# jbr_MDR1986VE1T register map
Registers are 32-bit, access not given, no defined reset value unless marked. A register's access mark holds for its fields unless they carry their own. Addresses are absolute; registers are grouped by the start of their names; [hi:lo] are bit positions; {n}, {i} and the like mark numbered series; 'fields as' and 'values as' point back to an identical list.

## GPIOF
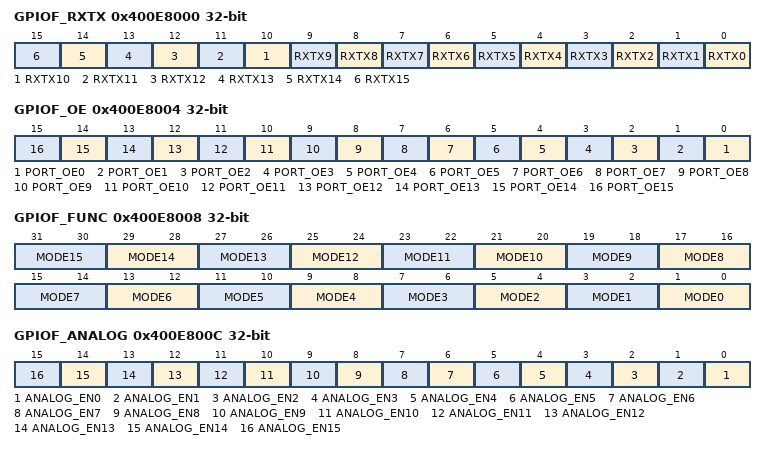
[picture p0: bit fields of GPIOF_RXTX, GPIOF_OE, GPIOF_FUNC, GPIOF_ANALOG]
0x400E8000 GPIOF_RXTX
  [n] RXTX{n} (n=0..15)
0x400E8004 GPIOF_OE
  [n] PORT_OE{n} (n=0..15)
0x400E8008 GPIOF_FUNC
  [2n+1:2n] MODE{n} (n=0..15)
0x400E800C GPIOF_ANALOG
  [n] ANALOG_EN{n} (n=0..15)
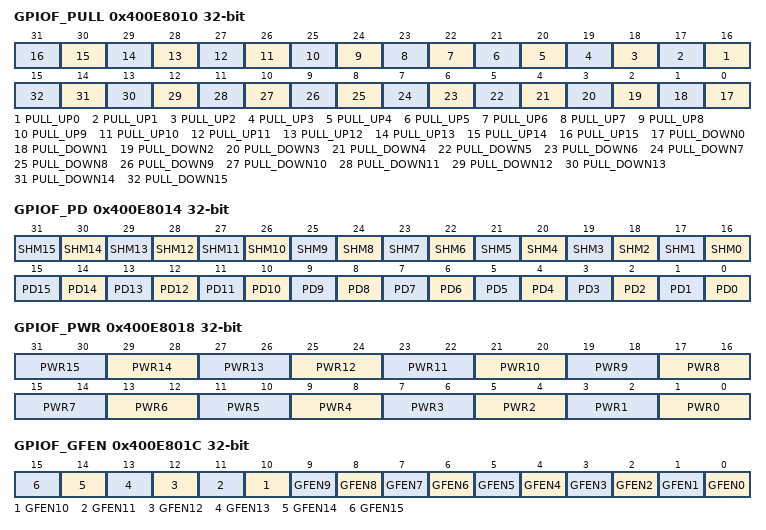
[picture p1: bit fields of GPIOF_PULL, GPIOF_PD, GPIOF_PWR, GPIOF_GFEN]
0x400E8010 GPIOF_PULL
  [n+16] PULL_UP{n} (n=0..15), [n] PULL_DOWN{n} (n=0..15)
0x400E8014 GPIOF_PD
  [n+16] SHM{n} (n=0..15), [n] PD{n} (n=0..15)
0x400E8018 GPIOF_PWR
  [2n+1:2n] PWR{n} (n=0..15)
0x400E801C GPIOF_GFEN
  [n] GFEN{n} (n=0..15)
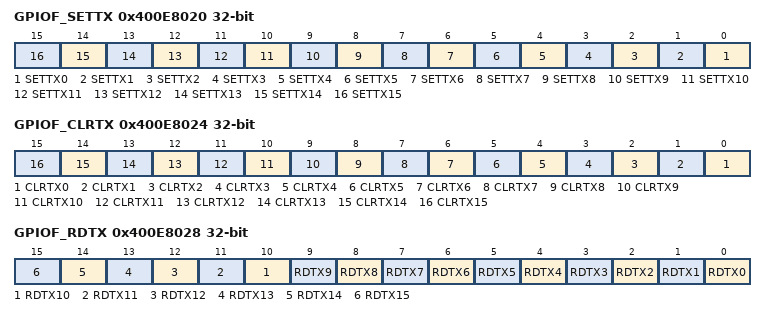
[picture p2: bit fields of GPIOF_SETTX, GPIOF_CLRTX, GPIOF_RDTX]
0x400E8020 GPIOF_SETTX
  [n] SETTX{n} (n=0..15)
0x400E8024 GPIOF_CLRTX
  [n] CLRTX{n} (n=0..15)
0x400E8028 GPIOF_RDTX
  [n] RDTX{n} (n=0..15)

## DMA
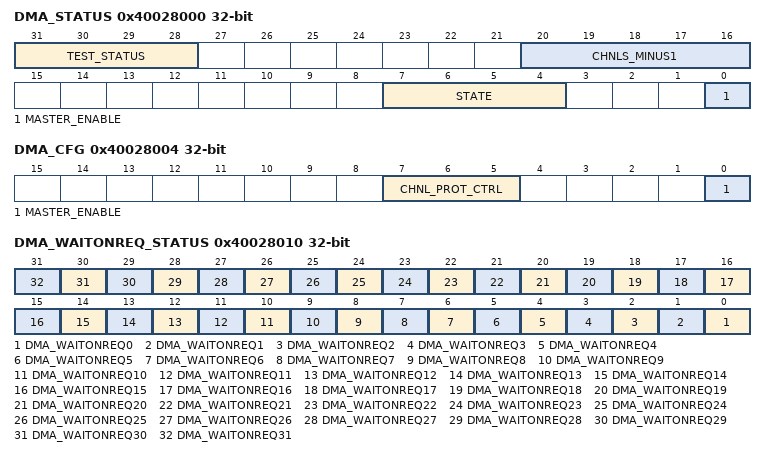
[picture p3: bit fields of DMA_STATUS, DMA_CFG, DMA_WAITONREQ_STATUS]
0x40028000 DMA_STATUS
  [31:28] TEST_STATUS, [20:16] CHNLS_MINUS1, [7:4] STATE, [0] MASTER_ENABLE
0x40028004 DMA_CFG
  [7:5] CHNL_PROT_CTRL, [0] MASTER_ENABLE
0x40028010 DMA_WAITONREQ_STATUS
  [n] DMA_WAITONREQ{n} (n=0..31)

## CHNL
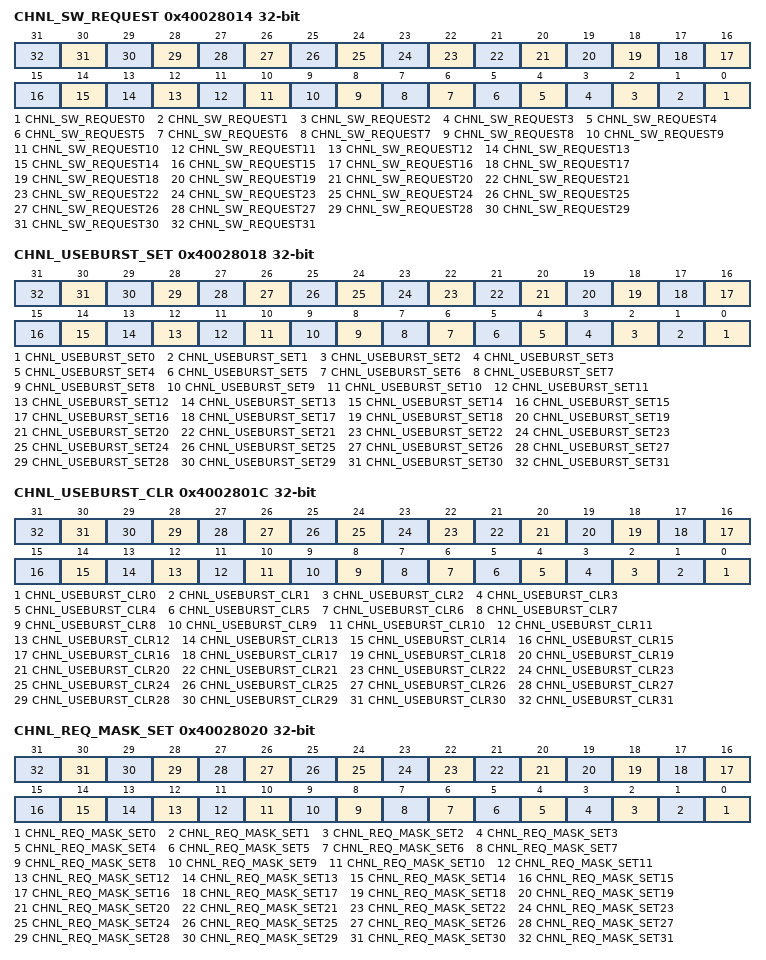
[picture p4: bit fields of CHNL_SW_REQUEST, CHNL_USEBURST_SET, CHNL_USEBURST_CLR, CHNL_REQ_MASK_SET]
0x40028014 CHNL_SW_REQUEST
  [n] CHNL_SW_REQUEST{n} (n=0..31)
0x40028018 CHNL_USEBURST_SET
  [n] CHNL_USEBURST_SET{n} (n=0..31)
0x4002801C CHNL_USEBURST_CLR
  [n] CHNL_USEBURST_CLR{n} (n=0..31)
0x40028020 CHNL_REQ_MASK_SET
  [n] CHNL_REQ_MASK_SET{n} (n=0..31)
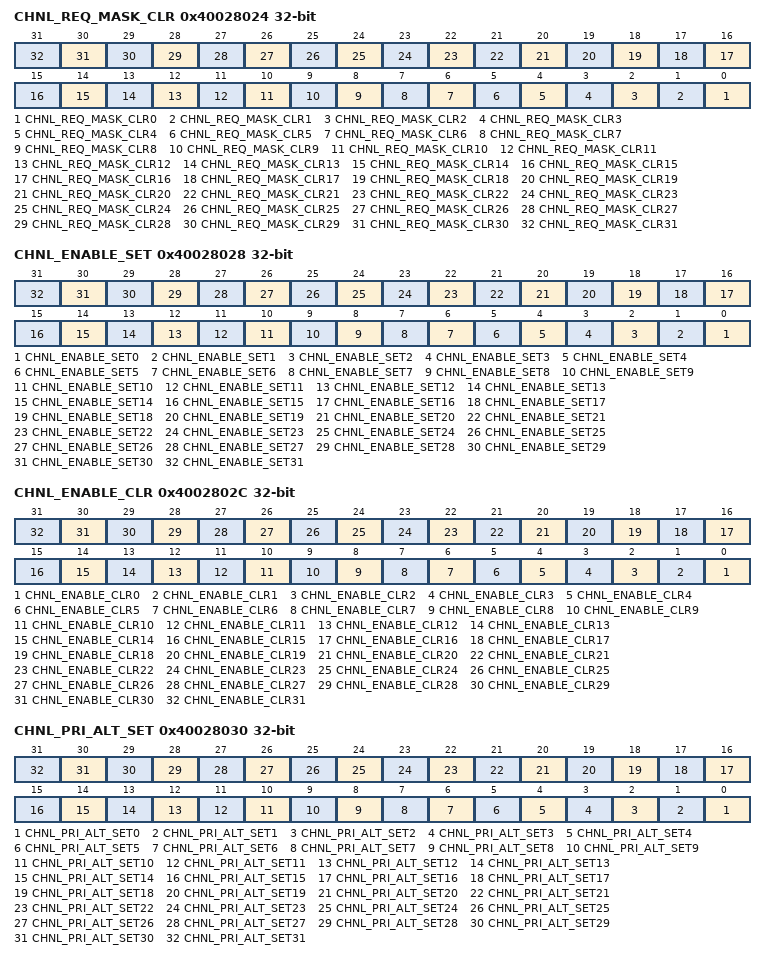
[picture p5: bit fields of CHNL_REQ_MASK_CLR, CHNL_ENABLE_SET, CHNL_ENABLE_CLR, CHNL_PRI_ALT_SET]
0x40028024 CHNL_REQ_MASK_CLR
  [n] CHNL_REQ_MASK_CLR{n} (n=0..31)
0x40028028 CHNL_ENABLE_SET
  [n] CHNL_ENABLE_SET{n} (n=0..31)
0x4002802C CHNL_ENABLE_CLR
  [n] CHNL_ENABLE_CLR{n} (n=0..31)
0x40028030 CHNL_PRI_ALT_SET
  [n] CHNL_PRI_ALT_SET{n} (n=0..31)
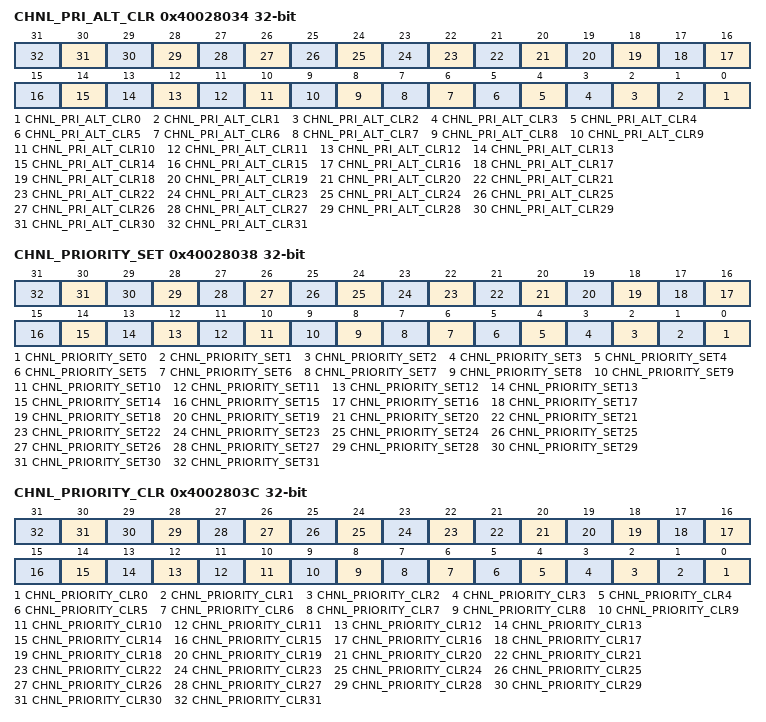
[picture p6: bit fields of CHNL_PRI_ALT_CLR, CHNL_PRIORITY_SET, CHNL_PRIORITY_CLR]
0x40028034 CHNL_PRI_ALT_CLR
  [n] CHNL_PRI_ALT_CLR{n} (n=0..31)
0x40028038 CHNL_PRIORITY_SET
  [n] CHNL_PRIORITY_SET{n} (n=0..31)
0x4002803C CHNL_PRIORITY_CLR
  [n] CHNL_PRIORITY_CLR{n} (n=0..31)

## IWDG
0x40068000 IWDG_KR 16-bit
  [15:0] KEY
0x40068004 IWDG_PR 16-bit
  [2:0] PR
0x40068008 IWDG_RLR 16-bit
  [11:0] RLR
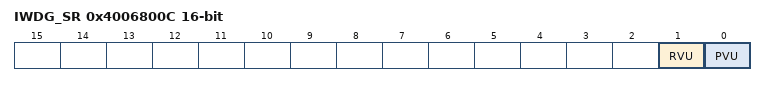
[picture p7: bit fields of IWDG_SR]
0x4006800C IWDG_SR 16-bit
  [1] RVU, [0] PVU

## WWDG
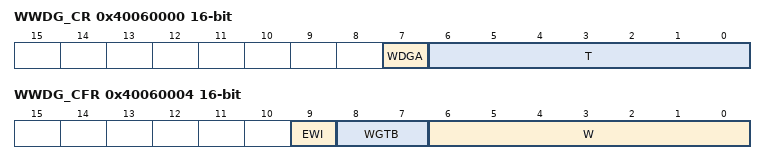
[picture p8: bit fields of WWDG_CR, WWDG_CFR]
0x40060000 WWDG_CR 16-bit
  [7] WDGA, [6:0] T
0x40060004 WWDG_CFR 16-bit
  [9] EWI, [8:7] WGTB, [6:0] W
0x40060008 WWDG_SR 16-bit
  [0] EWIF

## I2C
0x40050000 I2C_PRL
  [7:0] PR
0x40050004 I2C_PRH
  [7:0] PR
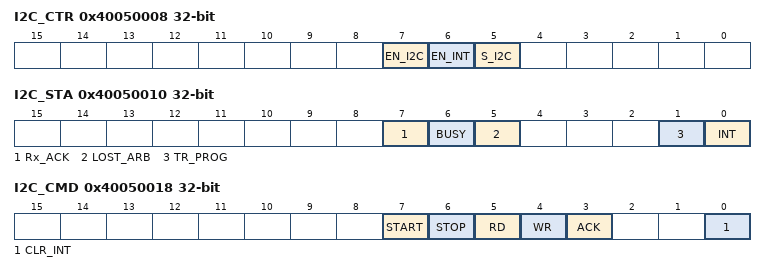
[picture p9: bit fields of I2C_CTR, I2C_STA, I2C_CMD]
0x40050008 I2C_CTR
  [7] EN_I2C, [6] EN_INT, [5] S_I2C
0x4005000C I2C_RXD
  [7:0] RXD
0x40050010 I2C_STA
  [7] Rx_ACK, [6] BUSY, [5] LOST_ARB, [1] TR_PROG, [0] INT
0x40050014 I2C_TXD
  [7:0] TXD
0x40050018 I2C_CMD
  [7] START, [6] STOP, [5] RD, [4] WR, [3] ACK, [0] CLR_INT

## SSP1
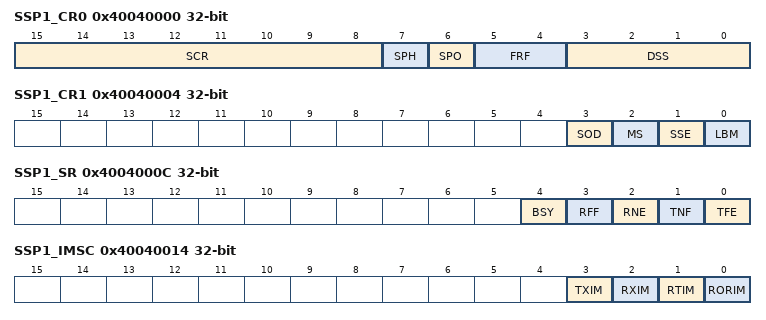
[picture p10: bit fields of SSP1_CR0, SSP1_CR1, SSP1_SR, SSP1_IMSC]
0x40040000 SSP1_CR0
  [15:8] SCR, [7] SPH, [6] SPO, [5:4] FRF, [3:0] DSS
0x40040004 SSP1_CR1
  [3] SOD, [2] MS, [1] SSE, [0] LBM
0x40040008 SSP1_DR
  [15:0] DATA
0x4004000C SSP1_SR
  [4] BSY, [3] RFF, [2] RNE, [1] TNF, [0] TFE
0x40040010 SSP1_CPSR
  [7:0] CPSDVSR
0x40040014 SSP1_IMSC
  [3] TXIM, [2] RXIM, [1] RTIM, [0] RORIM
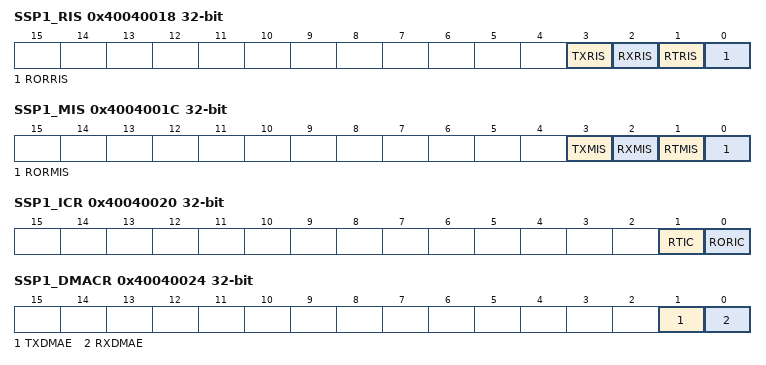
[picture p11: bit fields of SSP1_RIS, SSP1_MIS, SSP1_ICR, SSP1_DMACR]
0x40040018 SSP1_RIS
  [3] TXRIS, [2] RXRIS, [1] RTRIS, [0] RORRIS
0x4004001C SSP1_MIS
  [3] TXMIS, [2] RXMIS, [1] RTMIS, [0] RORMIS
0x40040020 SSP1_ICR
  [1] RTIC, [0] RORIC
0x40040024 SSP1_DMACR
  [1] TXDMAE, [0] RXDMAE

## SSP2
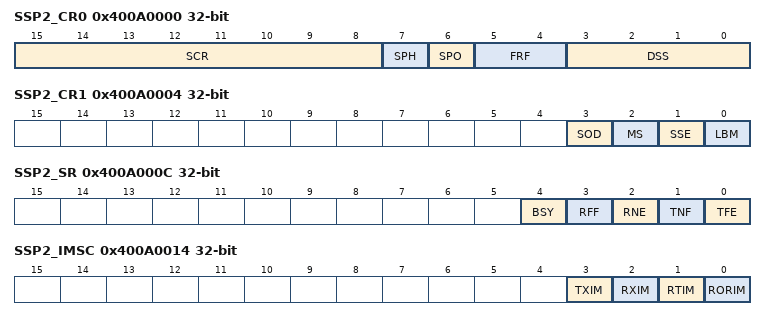
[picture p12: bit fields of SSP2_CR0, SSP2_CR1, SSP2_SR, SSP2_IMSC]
0x400A0000 SSP2_CR0
  [15:8] SCR, [7] SPH, [6] SPO, [5:4] FRF, [3:0] DSS
0x400A0004 SSP2_CR1
  [3] SOD, [2] MS, [1] SSE, [0] LBM
0x400A0008 SSP2_DR
  [15:0] DATA
0x400A000C SSP2_SR
  [4] BSY, [3] RFF, [2] RNE, [1] TNF, [0] TFE
0x400A0010 SSP2_CPSR
  [7:0] CPSDVSR
0x400A0014 SSP2_IMSC
  [3] TXIM, [2] RXIM, [1] RTIM, [0] RORIM
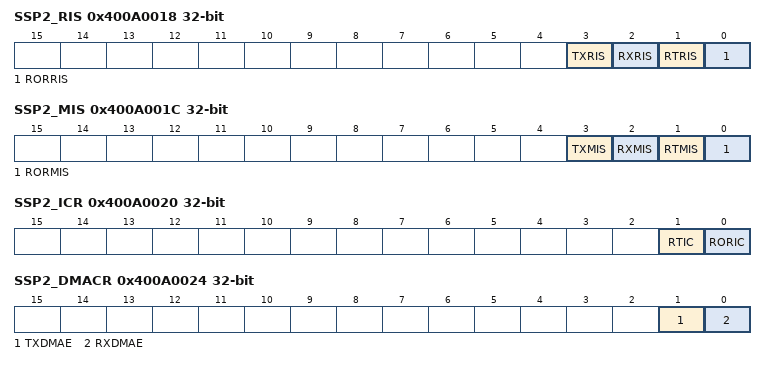
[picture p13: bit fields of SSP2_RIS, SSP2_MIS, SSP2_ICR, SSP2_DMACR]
0x400A0018 SSP2_RIS
  [3] TXRIS, [2] RXRIS, [1] RTRIS, [0] RORRIS
0x400A001C SSP2_MIS
  [3] TXMIS, [2] RXMIS, [1] RTMIS, [0] RORMIS
0x400A0020 SSP2_ICR
  [1] RTIC, [0] RORIC
0x400A0024 SSP2_DMACR
  [1] TXDMAE, [0] RXDMAE

## MIL
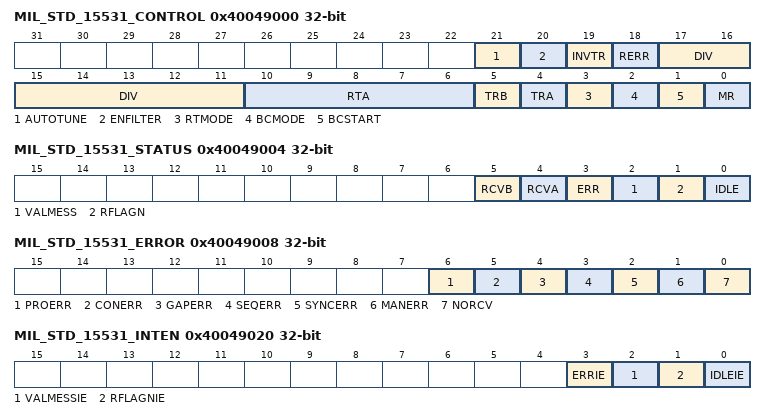
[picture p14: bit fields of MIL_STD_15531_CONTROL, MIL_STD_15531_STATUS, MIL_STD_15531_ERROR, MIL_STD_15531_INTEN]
0x40049000 MIL_STD_15531_CONTROL
  [21] AUTOTUNE, [20] ENFILTER, [19] INVTR, [18] RERR, [17:11] DIV, [10:6] RTA, [5] TRB, [4] TRA, [3] RTMODE, [2] BCMODE, [1] BCSTART, [0] MR
0x40049004 MIL_STD_15531_STATUS
  [5] RCVB, [4] RCVA, [3] ERR, [2] VALMESS, [1] RFLAGN, [0] IDLE
0x40049008 MIL_STD_15531_ERROR
  [6] PROERR, [5] CONERR, [4] GAPERR, [3] SEQERR, [2] SYNCERR, [1] MANERR, [0] NORCV
0x4004900C MIL_STD_15531_CommandWord1
0x40049010 MIL_STD_15531_CommandWord2
0x40049014 MIL_STD_15531_ModeData
0x40049018 MIL_STD_15531_StatusWord1
0x4004901C MIL_STD_15531_StatusWord2
0x40049020 MIL_STD_15531_INTEN
  [3] ERRIE, [2] VALMESSIE, [1] RFLAGNIE, [0] IDLEIE
0x40049024 MIL_STD_15531_MSG
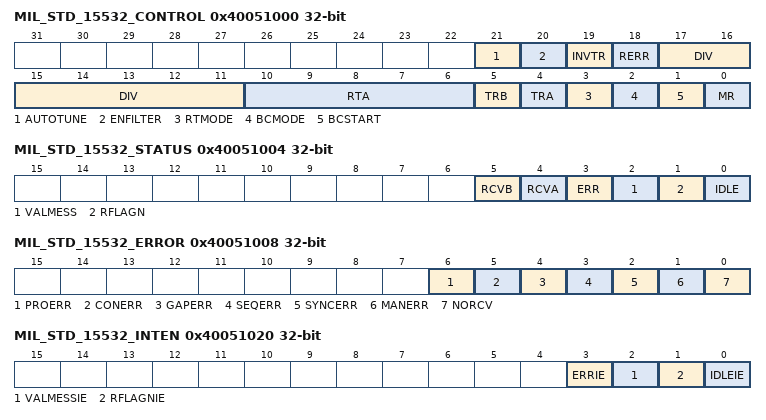
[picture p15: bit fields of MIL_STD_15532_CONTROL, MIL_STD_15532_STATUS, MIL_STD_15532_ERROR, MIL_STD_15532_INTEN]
0x40051000 MIL_STD_15532_CONTROL
  fields as MIL_STD_15531_CONTROL
0x40051004 MIL_STD_15532_STATUS
  [5] RCVB, [4] RCVA, [3] ERR, [2] VALMESS, [1] RFLAGN, [0] IDLE
0x40051008 MIL_STD_15532_ERROR
  fields as MIL_STD_15531_ERROR
0x4005100C MIL_STD_15532_CommandWord1
0x40051010 MIL_STD_15532_CommandWord2
0x40051014 MIL_STD_15532_ModeData
0x40051018 MIL_STD_15532_StatusWord1
0x4005101C MIL_STD_15532_StatusWord2
0x40051020 MIL_STD_15532_INTEN
  [3] ERRIE, [2] VALMESSIE, [1] RFLAGNIE, [0] IDLEIE
0x40051024 MIL_STD_15532_MSG

## ARINC429T
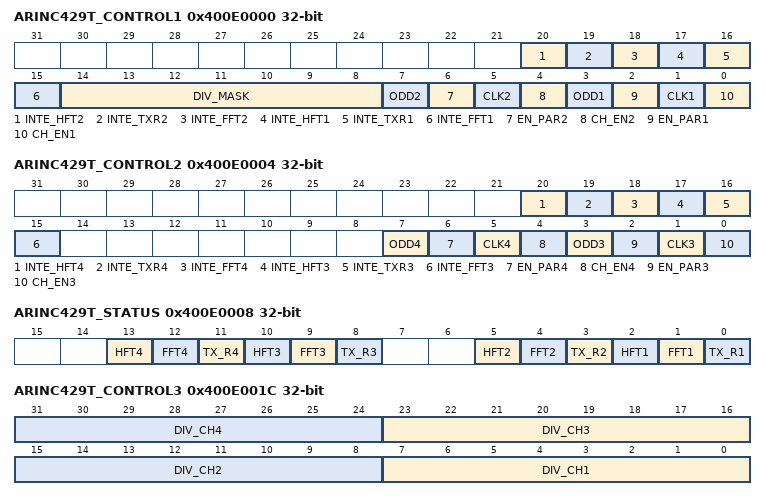
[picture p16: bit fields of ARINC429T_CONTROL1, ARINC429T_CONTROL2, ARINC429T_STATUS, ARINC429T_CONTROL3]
0x400E0000 ARINC429T_CONTROL1
  [20] INTE_HFT2, [19] INTE_TXR2, [18] INTE_FFT2, [17] INTE_HFT1, [16] INTE_TXR1, [15] INTE_FFT1, [14:8] DIV_MASK, [7] ODD2, [6] EN_PAR2, [5] CLK2, [4] CH_EN2, [3] ODD1, [2] EN_PAR1, [1] CLK1, [0] CH_EN1
0x400E0004 ARINC429T_CONTROL2
  [20] INTE_HFT4, [19] INTE_TXR4, [18] INTE_FFT4, [17] INTE_HFT3, [16] INTE_TXR3, [15] INTE_FFT3, [7] ODD4, [6] EN_PAR4, [5] CLK4, [4] CH_EN4, [3] ODD3, [2] EN_PAR3, [1] CLK3, [0] CH_EN3
0x400E0008 ARINC429T_STATUS
  [13] HFT4, [12] FFT4, [11] TX_R4, [10] HFT3, [9] FFT3, [8] TX_R3, [5] HFT2, [4] FFT2, [3] TX_R2, [2] HFT1, [1] FFT1, [0] TX_R1
{0x400E0008+4i} ARINC429T_DATA{i}_T (i=1..4)
0x400E001C ARINC429T_CONTROL3
  [8n-1:8n-8] DIV_CH{n} (n=1..4)

## ARINC429R
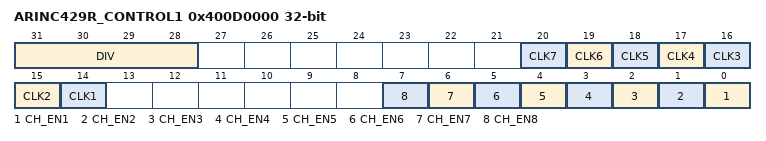
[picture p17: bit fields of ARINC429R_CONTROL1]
0x400D0000 ARINC429R_CONTROL1
  [31:28] DIV, [n+13] CLK{n} (n=1..7), [n-1] CH_EN{n} (n=1..8)
0x400D0004 ARINC429R_CONTROL2
  [n+16] SD_EN{n} (n=1..8), [n+2] LB_EN{n} (n=1..8), [2:0] DIV_6_4
0x400D0008 ARINC429R_CONTROL3
  [31] INTEHF, [30] INTEFF, [29] INTEER, [28] INTEDR, [n+13] SDI2_{n} (n=1..8), [n-1] SDI1_{n} (n=1..8)
0x400D000C ARINC429R_STATUS1
  [n+13] ERR{n} (n=1..8), [n-1] DR{n} (n=1..8)
0x400D0010 ARINC429R_STATUS2
  [n+13] HF{n} (n=1..8), [n-1] FF{n} (n=1..8)
0x400D0014 ARINC429R_CONTROL4
  [8n-1:8n-8] DIV_CH{n} (n=1..4)
0x400D0018 ARINC429R_CONTROL5
  [8n-33:8n-40] DIV_CH{n} (n=5..8)
0x400D001C ARINC429R_CHANNEL
0x400D0020 ARINC429R_LABEL
0x400D0024 ARINC429R_DATA_R
0x400D0068 ARINC429R_INTMASK
  [4n-1] IEDR{n} (n=1..8), [4n-2] IEER{n} (n=1..8), [4n-3] IEFF{n} (n=1..8), [4n-4] IEHF{n} (n=1..8)

## PHY
0x30000034 PHY_CONTROL 16-bit
  [15:11] PHYADD, [10] MDC, [9] MDIO_SEL, [8] MDI, [7] FX_EN, [3:1] MODE, [0] nRST
0x30000036 PHY_STATUS 16-bit
  [10] MDINT, [9] MDO, [8] FX_VALID, [7:6] COL, [5] CRS, [4] READY, [n] LED{n} (n=0..3)
